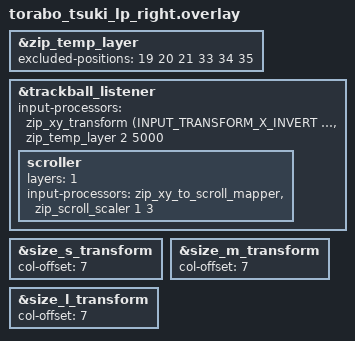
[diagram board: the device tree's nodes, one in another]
#include "torabo_tsuki_lp.dtsi"
#include <input/processors.dtsi>
#include <dt-bindings/zmk/input_transform.h>

/*コメントアウト、keymapの方に書く ここから*/
&zip_temp_layer {
    excluded-positions = <
        19 // U
        20 // I
        21 // O
        33 // J
        34 // K
        35 // l
    >;
};

&trackball_listener {
    input-processors = <&zip_xy_transform (INPUT_TRANSFORM_X_INVERT | INPUT_TRANSFORM_Y_INVERT)
                        &zip_temp_layer 2 5000
                        >;

    scroller {
        layers = <1>;
        input-processors = <&zip_xy_to_scroll_mapper
        &zip_scroll_scaler 1 3
        >;
    };
};
/*コメントアウト、keymapの方に書く ここまで*/

&size_s_transform {
    col-offset = <7>;
};

&size_m_transform {
    col-offset = <7>;
};

&size_l_transform {
    col-offset = <7>;
};
